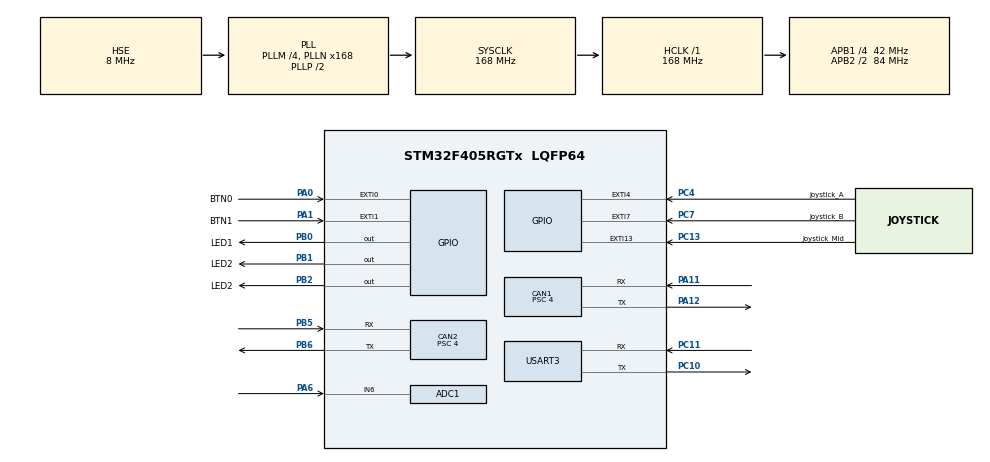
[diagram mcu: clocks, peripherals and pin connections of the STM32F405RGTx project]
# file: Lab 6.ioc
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ADC1.Channel-1\#ChannelRegularConversion=ADC_CHANNEL_6
ADC1.ContinuousConvMode=ENABLE
ADC1.DMAContinuousRequests=ENABLE
ADC1.EOCSelection=ADC_EOC_SEQ_CONV
ADC1.NbrOfConversion=1
ADC1.NbrOfConversionFlag=1
ADC1.Rank-1\#ChannelRegularConversion=1
ADC1.SamplingTime-1\#ChannelRegularConversion=ADC_SAMPLETIME_28CYCLES
ADC1.ScanConvMode=ENABLE
ADC1.master=1
CAN1.BS1=CAN_BS1_15TQ
CAN1.BS2=CAN_BS2_5TQ
CAN1.CalculateBaudRate=500000
CAN1.CalculateTimeBit=2000
CAN1.CalculateTimeQuantum=95.23809523809524
CAN1.Prescaler=4
CAN1.SJW=CAN_SJW_2TQ
CAN2.BS1=CAN_BS1_15TQ
CAN2.BS2=CAN_BS2_5TQ
CAN2.CalculateBaudRate=500000
CAN2.CalculateTimeBit=2000
CAN2.CalculateTimeQuantum=95.23809523809524
CAN2.Prescaler=4
CAN2.SJW=CAN_SJW_2TQ
Dma.ADC1.0.Direction=DMA_PERIPH_TO_MEMORY
Dma.ADC1.0.FIFOMode=DMA_FIFOMODE_DISABLE
Dma.ADC1.0.Instance=DMA2_Stream0
Dma.ADC1.0.MemDataAlignment=DMA_MDATAALIGN_HALFWORD
Dma.ADC1.0.MemInc=DMA_MINC_ENABLE
Dma.ADC1.0.Mode=DMA_CIRCULAR
Dma.ADC1.0.PeriphDataAlignment=DMA_PDATAALIGN_HALFWORD
Dma.ADC1.0.PeriphInc=DMA_PINC_DISABLE
Dma.ADC1.0.Priority=DMA_PRIORITY_MEDIUM
Dma.Request0=ADC1
FREERTOS.Events01=ECUCanTPStatusFlag,Dynamic,NULL;TesterCanTPStatusFlag,Dynamic,NULL
FREERTOS.INCLUDE_xEventGroupSetBitFromISR=1
FREERTOS.INCLUDE_xSemaphoreGetMutexHolder=1
FREERTOS.Tasks01=ECUTask,24,1024,ECUTask_Handler,As weak,NULL,Dynamic,NULL,NULL;TesterTask,24,1024,TesterTask_Handler,As weak,NULL,Dynamic,NULL,NULL
FREERTOS.configENABLE_FPU=1
FREERTOS.configLIBRARY_MAX_SYSCALL_INTERRUPT_PRIORITY=7
FREERTOS.configTOTAL_HEAP_SIZE=20000
FREERTOS.configUSE_NEWLIB_REENTRANT=1
Mcu.Family=STM32F4
Mcu.Name=STM32F405RGTx
Mcu.Package=LQFP64
NVIC.CAN1_RX0_IRQn=true\:7\:0\:true\:false\:true\:true\:true\:true\:true
NVIC.CAN1_RX1_IRQn=true\:7\:0\:false\:false\:true\:true\:true\:true\:true
NVIC.CAN1_SCE_IRQn=true\:7\:0\:false\:false\:true\:true\:true\:true\:true
NVIC.CAN2_RX0_IRQn=true\:7\:0\:false\:false\:true\:true\:true\:true\:true
NVIC.CAN2_RX1_IRQn=true\:7\:0\:false\:false\:true\:true\:true\:true\:true
NVIC.CAN2_SCE_IRQn=true\:7\:0\:false\:false\:true\:true\:true\:true\:true
NVIC.DMA2_Stream0_IRQn=true\:7\:0\:false\:false\:true\:true\:false\:true\:true
NVIC.EXTI0_IRQn=true\:7\:0\:false\:false\:true\:true\:true\:true\:true
NVIC.EXTI15_10_IRQn=true\:7\:0\:false\:false\:true\:true\:true\:true\:true
NVIC.EXTI1_IRQn=true\:7\:0\:false\:false\:true\:true\:true\:true\:true
NVIC.EXTI4_IRQn=true\:7\:0\:false\:false\:true\:true\:true\:true\:true
NVIC.EXTI9_5_IRQn=true\:7\:0\:false\:false\:true\:true\:true\:true\:true
NVIC.HASH_RNG_IRQn=true\:7\:0\:false\:false\:true\:true\:true\:true\:true
NVIC.PriorityGroup=NVIC_PRIORITYGROUP_4
NVIC.TIM6_DAC_IRQn=true\:15\:0\:false\:false\:true\:false\:false\:true\:true
NVIC.TimeBase=TIM6_DAC_IRQn
NVIC.TimeBaseIP=TIM6
NVIC.USART3_IRQn=true\:7\:0\:false\:false\:true\:true\:true\:true\:true
PA0-WKUP.GPIO_Label=BTN0
PA0-WKUP.GPIO_PuPd=GPIO_PULLUP
PA0-WKUP.Signal=GPXTI0
PA1.GPIO_Label=BTN1
PA1.GPIO_PuPd=GPIO_PULLUP
PA1.Signal=GPXTI1
PA11.Mode=CAN_Activate
PA11.Signal=CAN1_RX
PA12.Mode=CAN_Activate
PA12.Signal=CAN1_TX
PA13.Mode=Trace_Asynchronous_SW
PA13.Signal=SYS_JTMS-SWDIO
PA14.Mode=Trace_Asynchronous_SW
PA14.Signal=SYS_JTCK-SWCLK
PA6.Signal=ADCx_IN6
PB0.GPIO_Label=LED1
PB0.GPIO_Speed=GPIO_SPEED_FREQ_VERY_HIGH
PB0.Signal=GPIO_Output
PB1.GPIO_Label=LED2
PB1.GPIO_Speed=GPIO_SPEED_FREQ_VERY_HIGH
PB1.Signal=GPIO_Output
PB2.GPIO_Label=LED2
PB2.GPIO_Speed=GPIO_SPEED_FREQ_VERY_HIGH
PB2.Signal=GPIO_Output
PB3.Mode=Trace_Asynchronous_SW
PB3.Signal=SYS_JTDO-SWO
PB5.Mode=CAN_Activate
PB5.Signal=CAN2_RX
PB6.Mode=CAN_Activate
PB6.Signal=CAN2_TX
PC10.Mode=Asynchronous
PC10.Signal=USART3_TX
PC11.Mode=Asynchronous
PC11.Signal=USART3_RX
PC13-ANTI_TAMP.GPIO_Label=Joystick_Mid
PC13-ANTI_TAMP.GPIO_ModeDefaultEXTI=GPIO_MODE_IT_FALLING
PC13-ANTI_TAMP.GPIO_PuPd=GPIO_PULLUP
PC13-ANTI_TAMP.Signal=GPXTI13
PC4.GPIO_Label=Joystick_A
PC4.GPIO_ModeDefaultEXTI=GPIO_MODE_IT_FALLING
PC4.GPIO_PuPd=GPIO_PULLUP
PC4.Signal=GPXTI4
PC7.GPIO_Label=Joystick_B
PC7.GPIO_ModeDefaultEXTI=GPIO_MODE_IT_FALLING
PC7.GPIO_PuPd=GPIO_PULLUP
PC7.Signal=GPXTI7
PH0-OSC_IN.Mode=HSE-External-Oscillator
PH0-OSC_IN.Signal=RCC_OSC_IN
PH1-OSC_OUT.Mode=HSE-External-Oscillator
PH1-OSC_OUT.Signal=RCC_OSC_OUT
ProjectManager.HeapSize=0x200
ProjectManager.StackSize=0x400
ProjectManager.TargetToolchain=STM32CubeIDE
RCC.48MHZClocksFreq_Value=48000000
RCC.AHBFreq_Value=168000000
RCC.APB1CLKDivider=RCC_HCLK_DIV4
RCC.APB1Freq_Value=42000000
RCC.APB1TimFreq_Value=84000000
RCC.APB2CLKDivider=RCC_HCLK_DIV2
RCC.APB2Freq_Value=84000000
RCC.APB2TimFreq_Value=168000000
RCC.CortexFreq_Value=168000000
RCC.HCLKFreq_Value=168000000
RCC.HSE_VALUE=8000000
RCC.HSI_VALUE=16000000
RCC.LSE_VALUE=32768
RCC.PLLM=4
RCC.PLLN=168
RCC.PLLQ=7
RCC.PLLSourceVirtual=RCC_PLLSOURCE_HSE
RCC.SYSCLKFreq_VALUE=168000000
RCC.SYSCLKSource=RCC_SYSCLKSOURCE_PLLCLK
RCC.VCOOutputFreq_Value=336000000
SH.ADCx_IN6.0=ADC1_IN6,IN6
USART3.VirtualMode=VM_ASYNC
VP_FREERTOS_VS_CMSIS_V2.Mode=CMSIS_V2
VP_RNG_VS_RNG.Mode=RNG_Activate
VP_SYS_VS_tim6.Mode=TIM6
board=custom

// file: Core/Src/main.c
/* USER CODE BEGIN Header */
/**
  ******************************************************************************
  * @file           : main.c
  * @brief          : Main program body
  ******************************************************************************
  * @attention
  *
  * Copyright (c) 2022 STMicroelectronics.
  * All rights reserved.
  *
  * This software is licensed under terms that can be found in the LICENSE file
  * in the root directory of this software component.
  * If no LICENSE file comes with this software, it is provided AS-IS.
  *
  ******************************************************************************
  */
/* USER CODE END Header */
#include "main.h"
#include "cmsis_os.h"
#include "adc.h"
#include "can.h"
#include "dma.h"
#include "rng.h"
#include "usart.h"
#include "gpio.h"

void SystemClock_Config(void);
void MX_FREERTOS_Init(void);

int main(void)
{

  /* MCU Configuration--------------------------------------------------------*/

  /* Reset of all peripherals, Initializes the Flash interface and the Systick. */
  HAL_Init();

  /* Configure the system clock */
  SystemClock_Config();

  /* Initialize all configured peripherals */
  MX_GPIO_Init();
  MX_DMA_Init();
  MX_CAN1_Init();
  MX_CAN2_Init();
  MX_USART3_UART_Init();
  MX_ADC1_Init();
  MX_RNG_Init();

  /* Init scheduler */
  osKernelInitialize();  /* Call init function for freertos objects (in freertos.c) */
  MX_FREERTOS_Init();

  /* Start scheduler */
  osKernelStart();

  /* We should never get here as control is now taken by the scheduler */
  /* Infinite loop */
  while (1)
  {

  }
}

void SystemClock_Config(void)
{
  RCC_OscInitTypeDef RCC_OscInitStruct = {0};
  RCC_ClkInitTypeDef RCC_ClkInitStruct = {0};

  /** Configure the main internal regulator output voltage
  */
  __HAL_RCC_PWR_CLK_ENABLE();
  __HAL_PWR_VOLTAGESCALING_CONFIG(PWR_REGULATOR_VOLTAGE_SCALE1);

  /** Initializes the RCC Oscillators according to the specified parameters
  * in the RCC_OscInitTypeDef structure.
  */
  RCC_OscInitStruct.OscillatorType = RCC_OSCILLATORTYPE_HSE;
  RCC_OscInitStruct.HSEState = RCC_HSE_ON;
  RCC_OscInitStruct.PLL.PLLState = RCC_PLL_ON;
  RCC_OscInitStruct.PLL.PLLSource = RCC_PLLSOURCE_HSE;
  RCC_OscInitStruct.PLL.PLLM = 4;
  RCC_OscInitStruct.PLL.PLLN = 168;
  RCC_OscInitStruct.PLL.PLLP = RCC_PLLP_DIV2;
  RCC_OscInitStruct.PLL.PLLQ = 7;
  if (HAL_RCC_OscConfig(&RCC_OscInitStruct) != HAL_OK)
  {
    Error_Handler();
  }

  /** Initializes the CPU, AHB and APB buses clocks
  */
  RCC_ClkInitStruct.ClockType = RCC_CLOCKTYPE_HCLK|RCC_CLOCKTYPE_SYSCLK
                              |RCC_CLOCKTYPE_PCLK1|RCC_CLOCKTYPE_PCLK2;
  RCC_ClkInitStruct.SYSCLKSource = RCC_SYSCLKSOURCE_PLLCLK;
  RCC_ClkInitStruct.AHBCLKDivider = RCC_SYSCLK_DIV1;
  RCC_ClkInitStruct.APB1CLKDivider = RCC_HCLK_DIV4;
  RCC_ClkInitStruct.APB2CLKDivider = RCC_HCLK_DIV2;

  if (HAL_RCC_ClockConfig(&RCC_ClkInitStruct, FLASH_LATENCY_5) != HAL_OK)
  {
    Error_Handler();
  }
}

/* USER CODE BEGIN 4 */
//void HAL_CAN_RxFifo0MsgPendingCallback(CAN_HandleTypeDef *hcan)
//{
//	SyncPrintf("Fifo1 Int\r\n");
//}
//void HAL_CAN_RxFifo1MsgPendingCallback(CAN_HandleTypeDef *hcan)
//{
//	SyncPrintf("Fifo2 Int\r\n");
//}
/* USER CODE END 4 */

void HAL_TIM_PeriodElapsedCallback(TIM_HandleTypeDef *htim)
{
  if (htim->Instance == TIM6) {
    HAL_IncTick();
  }
}

void Error_Handler(void)
{
  __disable_irq();
  while (1)
  {
  }
}

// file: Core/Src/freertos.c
/* USER CODE BEGIN Header */
/**
  ******************************************************************************
  * File Name          : freertos.c
  * Description        : Code for freertos applications
  ******************************************************************************
  * @attention
  *
  * Copyright (c) 2022 STMicroelectronics.
  * All rights reserved.
  *
  * This software is licensed under terms that can be found in the LICENSE file
  * in the root directory of this software component.
  * If no LICENSE file comes with this software, it is provided AS-IS.
  *
  ******************************************************************************
  */
/* USER CODE END Header */

#include "FreeRTOS.h"
#include "task.h"
#include "main.h"
#include "cmsis_os.h"

/* Definitions for ECUTask */
osThreadId_t ECUTaskHandle;
const osThreadAttr_t ECUTask_attributes = {
  .name = "ECUTask",
  .stack_size = 1024 * 4,
  .priority = (osPriority_t) osPriorityNormal,
};
/* Definitions for TesterTask */
osThreadId_t TesterTaskHandle;
const osThreadAttr_t TesterTask_attributes = {
  .name = "TesterTask",
  .stack_size = 1024 * 4,
  .priority = (osPriority_t) osPriorityNormal,
};
/* Definitions for ECUCanTPStatusFlag */
osEventFlagsId_t ECUCanTPStatusFlagHandle;
const osEventFlagsAttr_t ECUCanTPStatusFlag_attributes = {
  .name = "ECUCanTPStatusFlag"
};
/* Definitions for TesterCanTPStatusFlag */
osEventFlagsId_t TesterCanTPStatusFlagHandle;
const osEventFlagsAttr_t TesterCanTPStatusFlag_attributes = {
  .name = "TesterCanTPStatusFlag"
};

void ECUTask_Handler(void *argument);
void TesterTask_Handler(void *argument);

void MX_FREERTOS_Init(void); /* (MISRA C 2004 rule 8.1) */

void MX_FREERTOS_Init(void) {
  /* USER CODE BEGIN Init */
	SyncPrintf_Init();
	ECUCanTPStatusFlagHandle = osEventFlagsNew(&ECUCanTPStatusFlag_attributes);
	TesterCanTPStatusFlagHandle = osEventFlagsNew(&TesterCanTPStatusFlag_attributes);
	TesterTaskHandle = osThreadNew(TesterTask_Handler, NULL, &TesterTask_attributes);

	ECUTaskHandle = osThreadNew(ECUTask_Handler, NULL, &ECUTask_attributes);

  /* USER CODE END Init */
/* USER CODE BEGIN Header */
/**
  ******************************************************************************
  * File Name          : freertos.c
  * Description        : Code for freertos applications
  ******************************************************************************
  * @attention
  *
  * Copyright (c) 2022 STMicroelectronics.
  * All rights reserved.
  *
  * This software is licensed under terms that can be found in the LICENSE file
  * in the root directory of this software component.
  * If no LICENSE file comes with this software, it is provided AS-IS.
  *
  ******************************************************************************
  */
/* USER CODE END Header */

}

__weak void ECUTask_Handler(void *argument)
{
  for(;;)
  {
    osDelay(1);
  }
}

__weak void TesterTask_Handler(void *argument)
{
  for(;;)
  {
    osDelay(1);
  }
}
